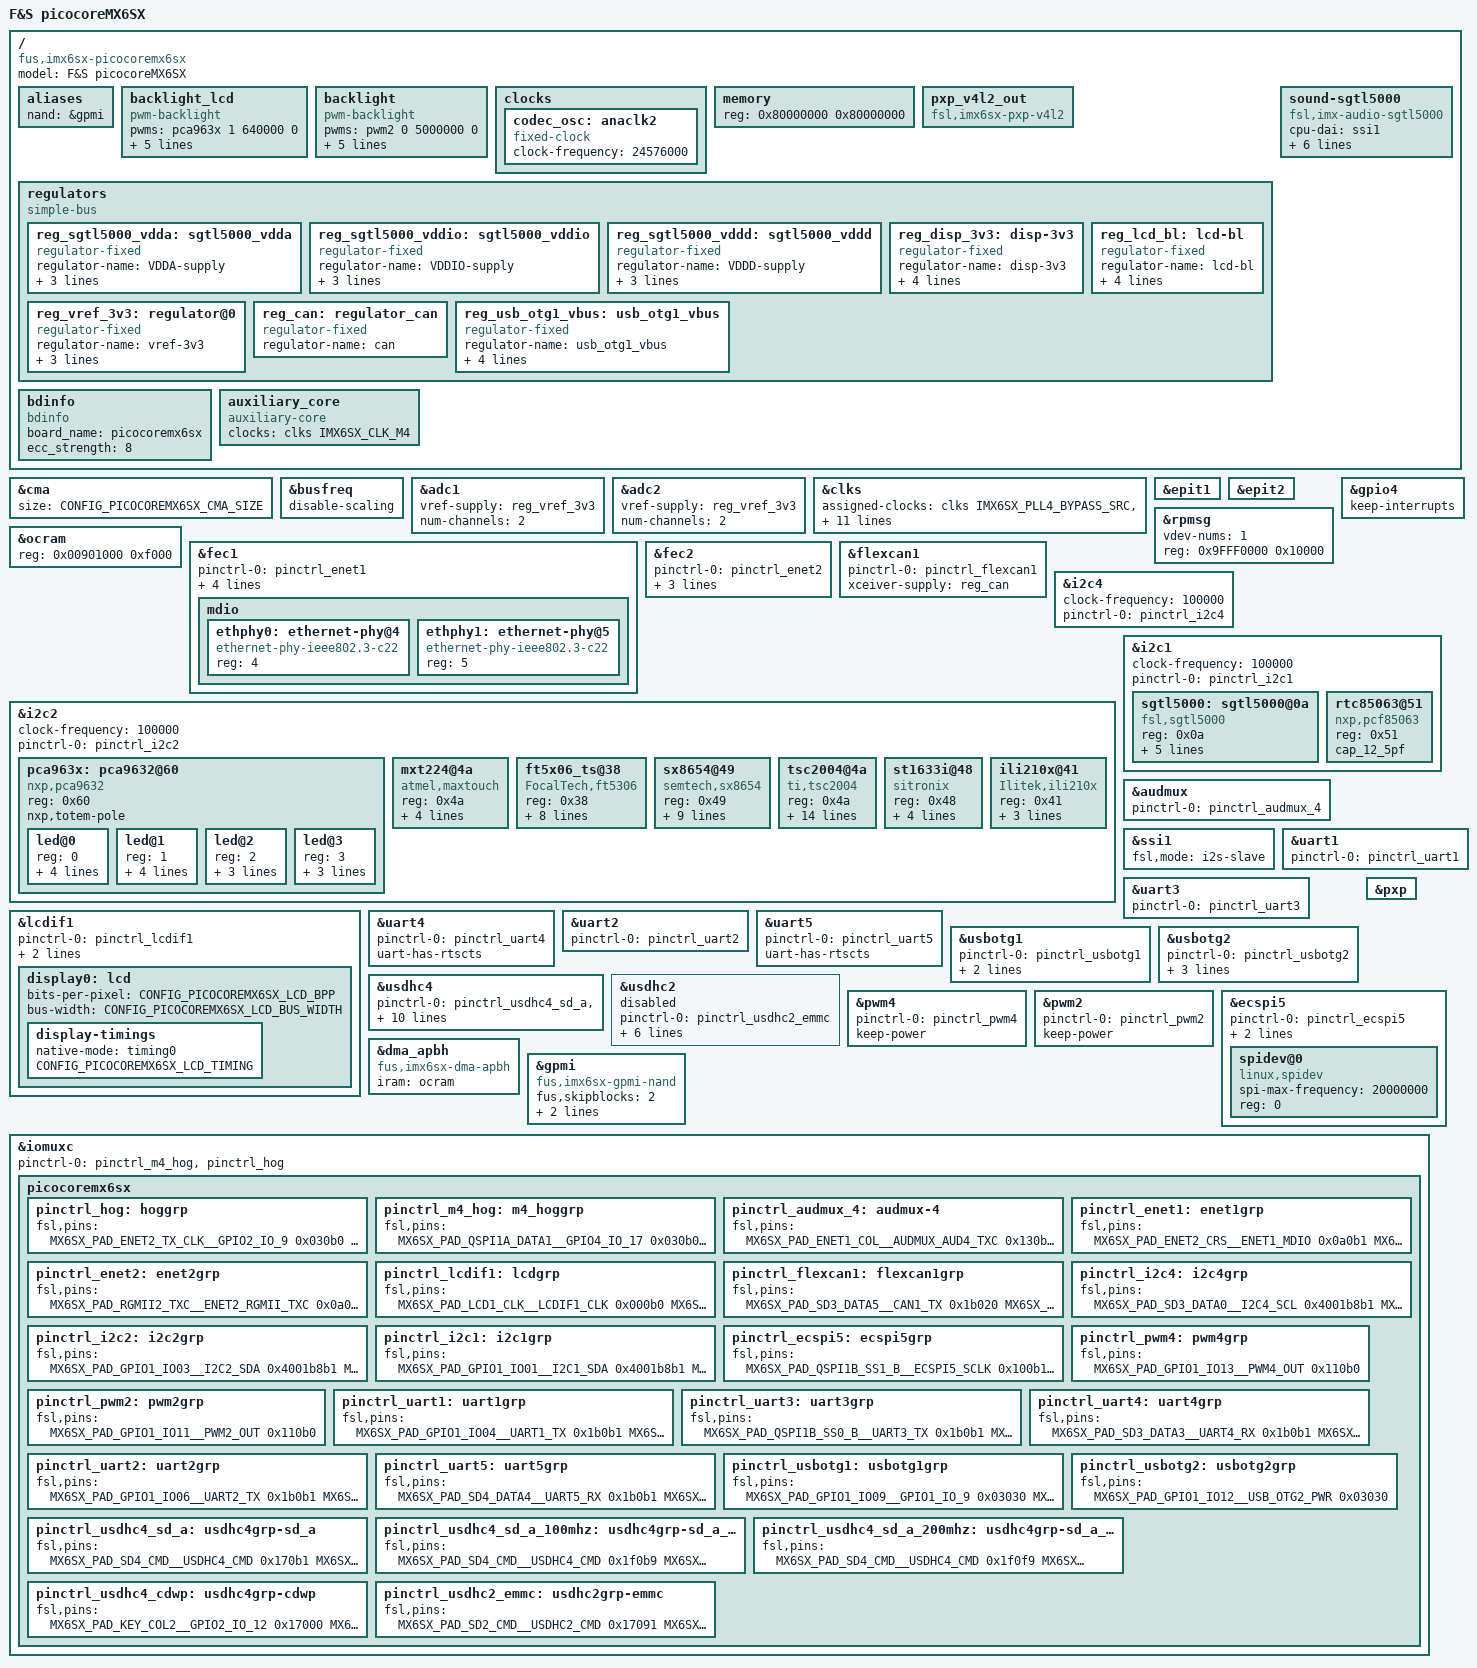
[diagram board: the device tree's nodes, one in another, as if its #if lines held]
/*
 * Copyright (C) 2016-2019 F&S Elektronik Systeme GmbH
 *
 * This program is free software; you can redistribute it and/or modify
 * it under the terms of the GNU General Public License version 2 as
 * published by the Free Software Foundation.
 */

/dts-v1/;

/* Set board revision as 3-digit number, e.g. 110 for board rev. 1.10 */
#define CONFIG_PICOCOREMX6SX_BOARD_REVISION	120

/* Activate this if you want to use the Cortex-M4 core */
// #define SUPPORT_M4

#define DISPLAY_NONE	0	/* No display on this port */
#define DISPLAY_LCD	1	/* LCD via RGB adapter */

/*
 * Set the display configuration:
 *
 * - If you have no display, set LCDIF0 to DISPLAY_NONE.
 * - If you have a display, set LCDIF0 to DISPLAY_LCD.
 */
#define CONFIG_PICOCOREMX6SX_LCDIF0		DISPLAY_LCD

/*
 * Configure LCD settings here (ignored if LCD is not used)
 */
#define CONFIG_PICOCOREMX6SX_LCD_BPP		32
#define CONFIG_PICOCOREMX6SX_LCD_BUS_WIDTH	24
#define CONFIG_PICOCOREMX6SX_LCD_TIMING \
lcd_wvga {				\
	clock-frequency = <33500000>;	\
	hactive = <800>;  		\
	vactive = <480>;		\
	hfront-porch = <40>;		\
	hback-porch = <88>;		\
	hsync-len = <128>;		\
	vback-porch = <33>;		\
	vfront-porch = <10>;		\
	vsync-len = <2>;		\
	hsync-active = <0>;		\
	vsync-active = <0>;		\
	de-active = <1>;		\
	pixelclk-active = <1>;		\
}

/* GPU is only available on CPU variants MCIMX6X3... and MCIMX6X4... */
#define CONFIG_PICOCOREMX6SX_GPU

/* Keep VLCD on when pca and touch are powered through VLCD */
//#define CONFIG_KEEP_VLCD_ON

/*
 * Configure touch screen:
 *
 * - 4-wire/5-wire analog resistive touch, touch controller on RGB LCD adapter
 * - PCAP touch based on Maxtouch controller (MXT224, etc.), on Touch Connector
 * - PCAP touch based on Focaltech controller (FT5x06), on Touch Connector
 * - PCAP touch based on Sitronix controller (ST1633i), on Touch Connector
 * - PCAP touch based on Ilitek controller (ILI12xx), on Touch Connector
 *
 * On picocore bb, all touches use the same interrupt line and I2C bus, so do not
 * select more than one entry! Select none if you do not need touch support.
 */
#define CONFIG_PICOCOREMX6SX_4WTOUCH_SX8655_RGBADAPTER
//#define CONFIG_PICOCOREMX6SX_4WTOUCH_TSC2004_RGBADAPTER
//#define CONFIG_PICOCOREMX6SX_CAPTOUCH_MXT224
//#define CONFIG_PICOCOREMX6SX_CAPTOUCH_FT5x06
//#define CONFIG_PICOCOREMX6SX_CAPTOUCH_SITRONIX
//#define CONFIG_PICOCOREMX6SX_CAPTOUCH_ILITEK

/* CMA: Set 320 MB for Continuous Memory Allocator */
#define CONFIG_PICOCOREMX6SX_CMA_SIZE 0x14000000

/* NAND */
/* eMMC */
/* Will be set by Uboot */


/* Network */
#define CONFIG_PICOCOREMX6SX_ETH0
#define CONFIG_PICOCOREMX6SX_ETH1

/* USB */
#define CONFIG_PICOCOREMX6SX_USB_OTG1
#define CONFIG_PICOCOREMX6SX_USB_HOST

/* CAN */
#define CONFIG_PICOCOREMX6SX_CAN_A

/* I2C */
#define CONFIG_PICOCOREMX6SX_I2C_A
#define CONFIG_PICOCOREMX6SX_I2C_B
#define CONFIG_PICOCOREMX6SX_I2C_C

/* ADC */
#define CONFIG_PICOCOREMX6SX_ADC_A
#define CONFIG_PICOCOREMX6SX_ADC_B

/* PWM and backlight brightness */
#define CONFIG_PICOCOREMX6SX_PWM_A
#define CONFIG_PICOCOREMX6SX_BL_CTRL

/* UART */
#define CONFIG_PICOCOREMX6SX_UART_A
#define CONFIG_PICOCOREMX6SX_UART_B
#define CONFIG_PICOCOREMX6SX_UART_C
#define CONFIG_PICOCOREMX6SX_UART_C_RTSCTS
#define CONFIG_PICOCOREMX6SX_UART_D
#define CONFIG_PICOCOREMX6SX_UART_E
#define CONFIG_PICOCOREMX6SX_UART_E_RTSCTS

/* SPI; SPI_B can only use CS2 if UART_C does not use RTS */
#define CONFIG_PICOCOREMX6SX_SPI_A

/* Audio */
#define CONFIG_PICOCOREMX6SX_AUDIO

/*
 * SD_A - External SD port with Card Detect (CD) and Write Protect (WP)
 * On PicoCore baseboard, this is the Micro-SD card slot with CD but without WP
 */
#define CONFIG_PICOCOREMX6SX_SD_A
#define CONFIG_PICOCOREMX6SX_SD_A_CD
//#define CONFIG_PICOCOREMX6SX_SD_A_WP

/* Check for invalid CONFIG combinations */

/*
 * Exclude devices from Linux that are used by the Cortex-M4 FreeRTOS examples
 *
 * - UART_B: used for debug output/UART examples
 * - SPI_B:  MISO/MOSI/CLK/CS1 used in SPI examples
 * - PWM_A:  used as LED output
 *
 * In addition the following pins are already predefined in FreeRTOS to be used
 * as arbitrary GPIOs. Please remove the comment of the appropriate line of
 * each device from which you use any signal in your own application.
 *
 * - SPI_A:  MISO/MOSI/CLK/CS1/CS2
 * - CAN_A:  TX/RX
 * - I2C_A:  SCL/SDA
 * - BL_CTL: (PWM)
 */
#ifdef SUPPORT_M4
#undef CONFIG_PICOCOREMX6SX_UART_B
#undef CONFIG_PICOCOREMX6SX_SPI_A
#undef CONFIG_PICOCOREMX6SX_CAN_A
#undef CONFIG_PICOCOREMX6SX_I2C_A
#undef CONFIG_PICOCOREMX6SX_BL_CTRL
#endif

/* If UART_C is not used, also RTS/CTS may not be used */
#ifndef CONFIG_PICOCOREMX6SX_UART_C
#undef CONFIG_PICOCOREMX6SX_UART_C_RTSCTS
#endif

#include "imx6sx.dtsi"
#include <dt-bindings/pwm/pwm.h>

/ {
	model = "F&S picocoreMX6SX";
	compatible = "fus,imx6sx-picocoremx6sx", "fsl,imx6sx";

	aliases {
		nand=&gpmi;
	};

#if defined(CONFIG_PICOCOREMX6SX_I2C_B) && (CONFIG_PICOCOREMX6SX_LCDIF0 == DISPLAY_LCD)
	backlight_lcd {
		compatible = "pwm-backlight";
		pwms = <&pca963x 1 640000 0>;
		power-supply = <&reg_lcd_bl>;
		brightness-levels = <0 1 5 10 18 28 41 56
				     73 92 113 137 163 192 222 255>;
		default-brightness-level = <14>;
		fb-names = "mxs-lcdif0";
	};
#endif

#if defined(CONFIG_PICOCOREMX6SX_BL_CTRL) && (CONFIG_PICOCOREMX6SX_LCDIF0 == DISPLAY_LCD)
	backlight {
		compatible = "pwm-backlight";
		pwms = <&pwm2 0 5000000 0>;
		power-supply = <&reg_lcd_bl>;
		brightness-levels = <0 1 5 10 18 28 41 56
				     73 92 113 137 163 192 222 255>;
		default-brightness-level = <14>;
		fb-names = "mxs-lcdif0";
	};
#endif

	clocks {
		codec_osc: anaclk2 {
			#clock-cells = <0>;
			compatible = "fixed-clock";
			clock-frequency = <24576000>;
		};
	};

	memory {
		reg = <0x80000000 0x80000000>;
	};

	pxp_v4l2_out {
		compatible = "fsl,imx6sx-pxp-v4l2", "fsl,imx6sl-pxp-v4l2";
		status = "okay";
	};

	regulators {
		compatible = "simple-bus";
		#address-cells = <1>;
		#size-cells = <0>;

#ifdef CONFIG_PICOCOREMX6SX_AUDIO
		/* SGTL5000 analog voltage */
		reg_sgtl5000_vdda: sgtl5000_vdda {
			compatible = "regulator-fixed";
			regulator-name = "VDDA-supply";
			regulator-min-microvolt = <3000000>;
			regulator-max-microvolt = <3000000>;
			regulator-always-on;
		};

		/* SGTL5000 I/O voltage */
		reg_sgtl5000_vddio: sgtl5000_vddio {
			compatible = "regulator-fixed";
			regulator-name = "VDDIO-supply";
			regulator-min-microvolt = <3300000>;
			regulator-max-microvolt = <3300000>;
			regulator-always-on;
		};

		/* SGTL5000 internal digital voltage */
		reg_sgtl5000_vddd: sgtl5000_vddd {
			compatible = "regulator-fixed";
			regulator-name = "VDDD-supply";
			regulator-min-microvolt = <1500000>;
			regulator-max-microvolt = <1500000>;
			regulator-always-on;
		};
#endif

#if (CONFIG_PICOCOREMX6SX_LCDIF0 == DISPLAY_LCD)
#ifndef CONFIG_KEEP_VLCD_ON
		reg_disp_3v3: disp-3v3 {
			compatible = "regulator-fixed";
			regulator-name = "disp-3v3";
			gpio = <&gpio3 27 0>;
			regulator-min-microvolt = <3300000>;
			regulator-max-microvolt = <3300000>;
			enable-active-high;
		};
#endif
#endif

#if defined(CONFIG_PICOCOREMX6SX_I2C_B) && (CONFIG_PICOCOREMX6SX_LCDIF0 == DISPLAY_LCD)
		reg_lcd_bl: lcd-bl {
			compatible = "regulator-fixed";
			regulator-name = "lcd-bl";
			gpio = <&pca963x 0 0>;
			regulator-min-microvolt = <3300000>;
			regulator-max-microvolt = <3300000>;
			enable-active-high;
		};
#endif

#if 0
		reg_atmel_mxt_vdd: atmel_mxt_vdd {
			compatible = "regulator-fixed";
			regulator-name = "mxt-3v3";
			status = "enabled";
		};

		reg_atmel_mxt_avdd: atmel_mxt_avdd {
			compatible = "regulator-fixed";
			regulator-name = "mxt-3v3";
			status = "enabled";
		};
#endif

		reg_vref_3v3: regulator@0 {
			compatible = "regulator-fixed";
			regulator-name = "vref-3v3";
			regulator-min-microvolt = <3300000>;
			regulator-max-microvolt = <3300000>;
			regulator-always-on;
		};

#ifdef CONFIG_PICOCOREMX6SX_CAN_A
		reg_can: regulator_can {
			compatible = "regulator-fixed";
			regulator-name = "can";
		};
#endif /* CONFIG_PICOCOREMX6SX_CAN_A */

#ifdef CONFIG_PICOCOREMX6SX_USB_OTG1
		/* USB_OTG1_PWR done by USB controller, no regulator needed */
		reg_usb_otg1_vbus: usb_otg1_vbus {
			compatible = "regulator-fixed";
			regulator-name = "usb_otg1_vbus";
			regulator-min-microvolt = <5000000>;
			regulator-max-microvolt = <5000000>;
			gpio = <&gpio1 9 0>;
			enable-active-high;
		};
#endif /* CONFIG_PICOCOREMX6SX_USB_OTG1 */

#if 0
		/* USB_OTG2_PWR done by USB controller, no regulator needed */
		reg_usb_otg2_vbus: usb_otg2_vbus {
			compatible = "regulator-fixed";
			regulator-name = "usb_otg2_vbus";
			regulator-min-microvolt = <5000000>;
			regulator-max-microvolt = <5000000>;
			gpio = <&gpio1 12 0>;
			enable-active-high;
		};
#endif
	};


#ifdef CONFIG_PICOCOREMX6SX_AUDIO
	sound-sgtl5000 {
		compatible = "fsl,imx-audio-sgtl5000";
		cpu-dai = <&ssi1>;
		audio-codec = <&sgtl5000>;
		model = "imx-sgtl5000";
		mux-int-port = <1>;  /* SSI1=1, SSI2=2, SSI3=7 */
		mux-ext-port = <4>;
		audio-routing =
			"LINE_IN", "Line In Jack",
//###			"MIC_IN", "Mic Jack",
//###			"Line Out Jack", "LINE_OUT",
			"Headphone Jack", "HP_OUT";
	};
#endif

	/* F&S board information */
	bdinfo {
		compatible = "bdinfo";
		board_name = "picocoremx6sx";
		ecc_strength = "8";
	};

#ifdef SUPPORT_M4
	/* F&S auxiliary core driver */
	auxiliary_core {
		compatible = "auxiliary-core";
		clocks = <&clks IMX6SX_CLK_M4>;
	};
#endif
};

/* RAM size for Continues Memory Allocator */
&cma {
	size = <CONFIG_PICOCOREMX6SX_CMA_SIZE>;
};

&busfreq {
	/* Disable bus frequency scaling, because reducing bus frequency to
	   24 MHz does not work with all types of DDR3 RAM */
	disable-scaling;
};

&adc1 {
	vref-supply = <&reg_vref_3v3>;
	num-channels = <2>;
	status = "okay";
};

&adc2 {
	vref-supply = <&reg_vref_3v3>;
	num-channels = <2>;
	status = "okay";
};

&clks {
	assigned-clocks = <&clks IMX6SX_PLL4_BYPASS_SRC>,
			  <&clks IMX6SX_PLL4_BYPASS>,
			  <&clks IMX6SX_CLK_PLL4_POST_DIV>;
	assigned-clock-parents = <&clks IMX6SX_CLK_LVDS2_IN>,
				 <&clks IMX6SX_PLL4_BYPASS_SRC>;
	assigned-clock-rates = <0>, <0>, <24576000>;
/* Needed for low power mode to tell A9 which clocks might be shared with M4 */
#ifdef SUPPORT_M4
	/* Shared memory in OCRAM, keep clear from Linux */
	fsl,shared-mem-addr = <0x91F000>;
	fsl,shared-mem-size = <0x1000>;
	fsl,shared-clks-number = <0x23>;
	fsl,shared-clks-index = <IMX6SX_CLK_PLL2_BUS
				 IMX6SX_CLK_PLL2_PFD0
				 IMX6SX_CLK_PLL2_PFD2
				 IMX6SX_CLK_PLL3_USB_OTG
				 IMX6SX_CLK_PLL3_PFD1
				 IMX6SX_CLK_PLL3_PFD2
				 IMX6SX_CLK_PLL3_PFD3
				 IMX6SX_CLK_PLL4_AUDIO
				 IMX6SX_CLK_PLL5_VIDEO
				 IMX6SX_CLK_OCRAM
				 IMX6SX_CLK_CAN1_SERIAL
				 IMX6SX_CLK_CAN1_IPG
				 IMX6SX_CLK_CAN2_SERIAL
				 IMX6SX_CLK_CAN2_IPG
				 IMX6SX_CLK_CANFD
				 IMX6SX_CLK_ECSPI1
				 IMX6SX_CLK_ECSPI2
				 IMX6SX_CLK_ECSPI3
				 IMX6SX_CLK_ECSPI4
				 IMX6SX_CLK_ECSPI5
				 IMX6SX_CLK_QSPI1
				 IMX6SX_CLK_QSPI2
				 IMX6SX_CLK_SSI1
				 IMX6SX_CLK_SSI2
				 IMX6SX_CLK_SSI3
				 IMX6SX_CLK_UART_SERIAL
				 IMX6SX_CLK_UART_IPG
				 IMX6SX_CLK_PERIPH_CLK2_SEL
				 IMX6SX_CLK_DUMMY
				 IMX6SX_CLK_I2C1
				 IMX6SX_CLK_I2C2
				 IMX6SX_CLK_I2C3
				 IMX6SX_CLK_I2C4
				 IMX6SX_CLK_EPIT1
				 IMX6SX_CLK_EPIT2>;
#endif
};

#ifdef SUPPORT_M4
/* epit1 and epit2 are used by Cortex-M4 examples for timing purposes */
&epit1{
	status = "okay";
};


&epit2{
	status = "okay";
};

/* rpmsg is used for communication between Cortex-A9 and Cortex-M4 cores */

&rpmsg{
	/*
	 * 64K for one rpmsg instance, default using 2 rpmsg instances:
	 * --0x9FF00000~0x9FF0FFFF: pmic,pm,audio,keys,gpio,sensor
	 * --0x9FF10000~0x9FF1FFFF: pingpong,virtual tty
	 */
	vdev-nums = <1>;
	reg = <0x9FFF0000 0x10000>;
	status = "okay";
};

/* Keep interrupts on GPIO4 if M4 already owns it */
&gpio4 {
	keep-interrupts;
};

/*
 * OCRAM usage (128KB):
 *   0x00900000 - 0x00900FFF: Cortex-A9/Linux: CPU idle + bus frequency code
 *   0x00901000 - 0x0090FFFF: Cortex-A9/Linux: DMA descriptors, GPU
 *   0x00910000 - 0x0091EFFF: Cortex-M4/FreeRTOS: Code/Data
 *   0x0091F000 - 0x0091FFFF: Cortex-A9+M4: Shared memory for shared clocks
 */
&ocram {
	reg = <0x00901000 0xf000>;
};
#endif

#ifdef CONFIG_PICOCOREMX6SX_ETH0
&fec1 {
	pinctrl-names = "default";
	pinctrl-0 = <&pinctrl_enet1>;
	phy-mode = "rgmii-id";
	phy-handle = <&ethphy0>;
	phy-supply = <&reg_vref_3v3>;
	fsl,magic-packet;
	status = "okay";

	/* The MDIO bus on FEC1 holds both PHYs */
	mdio {
		#address-cells = <1>;
		#size-cells = <0>;

		ethphy0: ethernet-phy@4 {
			compatible = "ethernet-phy-ieee802.3-c22";
			reg = <4>;
		};

#ifdef CONFIG_PICOCOREMX6SX_ETH1
		ethphy1: ethernet-phy@5 {
			compatible = "ethernet-phy-ieee802.3-c22";
			reg = <5>;
		};
#endif
	};
};
#endif /* CONFIG_PICOCOREMX6SX_ETH0 */

#ifdef CONFIG_PICOCOREMX6SX_ETH1
&fec2 {
	pinctrl-names = "default";
	pinctrl-0 = <&pinctrl_enet2>;
	phy-mode = "rgmii-id";
	phy-handle = <&ethphy1>;
	fsl,magic-packet;
	status = "okay";
};
#endif /* CONFIG_PICOCOREMX6SX_ETH1 */

#ifdef CONFIG_PICOCOREMX6SX_CAN_A
&flexcan1 {
	pinctrl-names = "default";
	pinctrl-0 = <&pinctrl_flexcan1>;
	xceiver-supply = <&reg_can>;
	status = "okay";
};
#endif

#ifdef CONFIG_PICOCOREMX6SX_I2C_A
&i2c4 {
	clock-frequency = <100000>;
	pinctrl-names = "default";
	pinctrl-0 = <&pinctrl_i2c4>;
	status = "okay";
};

#endif /* CONFIG_PICOCOREMX6SX_I2C_A */

#ifdef CONFIG_PICOCOREMX6SX_I2C_B
/*
 * I2C_A implemented via I2C2
 * On picocore bb: RGB adapter, SX8655, touch connnector, feature connector
 */
&i2c2 {
	clock-frequency = <100000>;
	pinctrl-names = "default";
	pinctrl-0 = <&pinctrl_i2c2>;
	status = "okay";

	pca963x: pca9632@60 {
		compatible = "nxp,pca9632";
		reg = <0x60>;
		nxp,totem-pole;
		#address-cells = <1>;
		#size-cells = <0>;
		#pwm-cells = <3>;
		#gpio-cells = <2>;
		led@0 {
			reg = <0>;
			label = "0-PWRCTL";
			type = "GPIO";
			default-on;		/* or: keep-value */
			active-high;
		};
		led@1 {
			reg = <1>;
			label = "1-LEDCTRL";
			type = "PWM";
			default-on;		/* or: keep-value */
			active-low;
		};
		led@2 {
			reg = <2>;
			label = "2-ROTATE";
			type = "GPIO";
			active-high;		/* optionally: keep value */
		};
		led@3 {
			reg = <3>;
			label = "3-unused";
			type = "LED";
			active-low;
		};
	};

#ifdef CONFIG_PICOCOREMX6SX_CAPTOUCH_MXT224
	mxt224@4a {
		compatible = "atmel,maxtouch";
		reg = <0x4a>;
		interrupt-parent = <&gpio7>;
		interrupts = <0 2>;
		atmel,cfg_name = "atmel/mxt224.cfg";
		atmel,reset-gpio = <&gpio3 21 GPIO_ACTIVE_LOW>;
#if 0
		atmel,suspend-mode = <2>;
		vdd = <&reg_atmel_mxt_vdd>;
		avdd = <&reg_atmel_mxt_avdd>;
#endif
	};
#endif

        /* Touch driver Focaltech  */
#if 0
	/* Mainline driver, may only work on EDT displays */
	edt-ft5x06@38 {
		compatible = "edt,edt-ft5306";
		reg = <0x38>;
		threshold = <25>;
		gain = <8>;
		offset = <0>;
		interrupt-parent = <&gpio7>;
		interrupts = <0 IRQ_TYPE_EDGE_FALLING>;
		reset-gpios = <&gpio3 21 GPIO_ACTIVE_LOW>;
	};
#else

#ifdef CONFIG_PICOCOREMX6SX_CAPTOUCH_FT5x06
	/* F&S driver V3.0 */
	ft5x06_ts@38 {
		compatible = "FocalTech,ft5306";
		reg = <0x38>;
		fingers = <2>;
		touchscreen-size-x = <800>;
		touchscreen-size-y = <480>;
		threshold = <25>;
		interrupt-parent = <&gpio7>;
		interrupts = <0 IRQ_TYPE_EDGE_FALLING>;
		reset-gpios = <&gpio3 21 GPIO_ACTIVE_LOW>;
		linux,wakeup;
	};
#endif

#endif

	/* Touch driver SX8654 */
#ifdef CONFIG_PICOCOREMX6SX_4WTOUCH_SX8655_RGBADAPTER
	sx8654@49 {
		compatible = "semtech,sx8654";
		reg = <0x49>;
		touchrate = <0x30>;
		powdly = <0x06>;
		filt = <0x02>;
		setdly = <0x08>;
		pinctrl-names = "default";
		/*pinctrl-0 = <&pinctrl_touchscreen>;*/
		interrupt-parent = <&gpio1>;
		interrupts = <8 IRQ_TYPE_EDGE_FALLING>;
		reset-gpio = <&gpio3 21 GPIO_ACTIVE_LOW>;
		x-rev;
		y-rev;
	};
#endif

#ifdef CONFIG_PICOCOREMX6SX_4WTOUCH_TSC2004_RGBADAPTER
	/* 4/5 wire analog resistive touch on RGB-Adapter */
	tsc2004@4a {
		compatible = "ti,tsc2004";
		reg = <0x4a>;
		vio-supply = <&reg_vref_3v3>;
		interrupts-extended = <&gpio1 8 IRQ_TYPE_EDGE_FALLING>;
		reset-gpio = <&gpio3 21 GPIO_ACTIVE_LOW>;
		touchscreen-fuzz-x = <4>;
		touchscreen-fuzz-y = <7>;
		touchscreen-fuzz-pressure = <20>;
		touchscreen-size-x = <4096>;
		touchscreen-size-y = <4096>;
		touchscreen-max-pressure = <2048>;
		touchscreen-inverted-y;
		ti,x-plate-ohms = <280>;
		ti,pre-charge-time = <4>;
		ti,sense-time-sel = <3>;
	};
#endif

#ifdef CONFIG_PICOCOREMX6SX_CAPTOUCH_SITRONIX
	/* Sitronix PCAP touch on Touch-Connector (I2C) */
	st1633i@48 {
		compatible = "sitronix";
		reg = <0x48>;
		swap-xy;
		interrupt-parent = <&gpio7>;
		interrupts = <0 IRQ_TYPE_EDGE_FALLING>;
		reset-gpio = <&gpio3 21 GPIO_ACTIVE_LOW>;
	};
#endif

#ifdef CONFIG_PICOCOREMX6SX_CAPTOUCH_ILITEK
	/* Ilitek PCAP touch on Touch-Connector (I2C) */
	ili210x@41 {
		compatible = "Ilitek,ili210x";
		reg = <0x41>;
		interrupt-parent = <&gpio7>;
		interrupts = <0 IRQ_TYPE_EDGE_FALLING>;
		reset-gpio = <&gpio3 21 GPIO_ACTIVE_LOW>;
	};
#endif

#if 0
	egalax_ts@04 {
		compatible = "eeti,egalax_ts";
		reg = <0x04>;
		interrupt-parent = <&gpio6>;
		interrupts = <22 2>;
		wakeup-gpios = <&gpio6 22 0>;
	};
#endif
};
#endif /* CONFIG_PICOCOREMX6SX_I2C_B */


#ifdef CONFIG_PICOCOREMX6SX_I2C_C
/*
 * I2C_C implemented via I2C1; used for on-board RTC, on-board LVDS connector;
 * On picocore bb: Audio Codec (SGTL5000), HDMI
 */
&i2c1 {
	clock-frequency = <100000>;
	pinctrl-names = "default";
	pinctrl-0 = <&pinctrl_i2c1>;
	status = "okay";

#ifdef CONFIG_PICOCOREMX6SX_AUDIO
	sgtl5000: sgtl5000@0a {
		compatible = "fsl,sgtl5000";
		reg = <0x0a>;
		mono2both;
		clocks = <&clks IMX6SX_CLK_AUDIO>;
		VDDA-supply = <&reg_sgtl5000_vdda>;
		VDDIO-supply = <&reg_sgtl5000_vddio>;
		VDDD-supply = <&reg_sgtl5000_vddd>;
	};
#endif

	rtc85063@51 {
		compatible = "nxp,pcf85063";
		reg = <0x51>;
		cap_12_5pf;
	};
};
#endif /* CONFIG_PICOCOREMX6SX_I2C_C */

#ifdef CONFIG_PICOCOREMX6SX_AUDIO
&audmux {
	pinctrl-names = "default";
	pinctrl-0 = <&pinctrl_audmux_4>;
	status = "okay";
};

&ssi1 {
//###	fsl,mode = "i2s-master";
	fsl,mode = "i2s-slave";
	status = "okay";
};
#endif /* CONFIG_PICOCOREMX6SX_AUDIO */

#if (CONFIG_PICOCOREMX6SX_LCDIF0 == DISPLAY_LCD)
&lcdif1 {
	pinctrl-names = "default";
	pinctrl-0 = <&pinctrl_lcdif1>;		/* Remove when already active */
	display = <&display0>;			/* Remove when already active */
#ifndef CONFIG_KEEP_VLCD_ON
	lcd-supply = <&reg_disp_3v3>;
#endif
	// pattern = <5>;
	status = "okay";

	display0: lcd {
		bits-per-pixel = <CONFIG_PICOCOREMX6SX_LCD_BPP>;
		bus-width = <CONFIG_PICOCOREMX6SX_LCD_BUS_WIDTH>;

		display-timings {
			native-mode = <&timing0>;
			timing0: CONFIG_PICOCOREMX6SX_LCD_TIMING;
		};
	};
};
#endif /* CONFIG_PICOCOREMX6SX_LCDIF0 */

#ifndef CONFIG_PICOCOREMX6SX_GPU
&gpu {
	status = "disabled";
};
#endif


#ifdef CONFIG_PICOCOREMX6SX_UART_A
/* UART_A implemented by UART1: TXD, RXD only */
&uart1 {
	pinctrl-names = "default";
	pinctrl-0 = <&pinctrl_uart1>;
	status = "okay";
};
#endif /* CONFIG_PICOCOREMX6SX_UART_A */

#ifdef CONFIG_PICOCOREMX6SX_UART_B
/* UART_B implemented by UART3: TXD, RXD only */
&uart3 {
	pinctrl-names = "default";
	pinctrl-0 = <&pinctrl_uart3>;
	status = "okay";
};
#endif /* CONFIG_PICOCOREMX6SX_UART_B */

#ifdef CONFIG_PICOCOREMX6SX_UART_C
/* UART_C implemented by UART4: TXD, RXD,  RTS, CTS */
&uart4 {
	pinctrl-names = "default";
	pinctrl-0 = <&pinctrl_uart4>;
#ifdef CONFIG_PICOCOREMX6SX_UART_C_RTSCTS
	uart-has-rtscts;
#endif
	status = "okay";
};
#endif /* CONFIG_PICOCOREMX6SX_UART_C */

#ifdef CONFIG_PICOCOREMX6SX_UART_D
/* UART_D implemented by UART2: TXD, RXD only */
&uart2 {
	pinctrl-names = "default";
	pinctrl-0 = <&pinctrl_uart2>;
	status = "okay";
};
#endif /* CONFIG_PICOCOREMX6SX_UART_D */

#ifdef CONFIG_PICOCOREMX6SX_UART_E
/*  UART_E implemented by UART5: TXD, RXD, RTS, CTS */
&uart5 {
	pinctrl-names = "default";
	pinctrl-0 = <&pinctrl_uart5>;
#ifdef CONFIG_PICOCOREMX6SX_UART_E_RTSCTS
	uart-has-rtscts;
#endif
	status = "okay";
};
#endif /* CONFIG_PICOCOREMX6SX_UART_E */

#ifdef CONFIG_PICOCOREMX6SX_USB_OTG1
&usbotg1 {
	pinctrl-names = "default";
	pinctrl-0 = <&pinctrl_usbotg1>;
	vbus-supply = <&reg_usb_otg1_vbus>;
	disable-over-current;
	status = "okay";
};
#endif

#ifdef CONFIG_PICOCOREMX6SX_USB_HOST
&usbotg2 {
	pinctrl-names = "default";
	pinctrl-0 = <&pinctrl_usbotg2>;
//	vbus-supply = <&reg_usb_otg2_vbus>;
	dr_mode = "host";
	pwr-active-high;
	disable-over-current;
	status = "okay";
};
#endif

#ifdef CONFIG_PICOCOREMX6SX_SD_A
/* SD_A implemented via USDHC4 on board revisions since 1.20 */
&usdhc4 {
	pinctrl-names = "default", "state_100mhz", "state_200mhz";
	pinctrl-0 = <&pinctrl_usdhc4_sd_a &pinctrl_usdhc4_cdwp>;
	pinctrl-1 = <&pinctrl_usdhc4_sd_a_100mhz &pinctrl_usdhc4_cdwp>;
	pinctrl-2 = <&pinctrl_usdhc4_sd_a_200mhz &pinctrl_usdhc4_cdwp>;
#ifdef CONFIG_PICOCOREMX6SX_SD_A_CD
	cd-gpios = <&gpio2 12 GPIO_ACTIVE_LOW>;
#else
	non-removable;
#endif
#ifdef CONFIG_PICOCOREMX6SX_SD_A_WP
	wp-gpios = <&gpio2 17 GPIO_ACTIVE_HIGH>;
#endif
	bus-width = <4>;
	vmmc-supply = <&reg_vref_3v3>;	/* VDD */
	keep-power-in-suspend;
	status = "okay";
};
#endif /* CONFIG_PICOCOREMX6SX_SD_A */

/* Keep disabled. Will be activated by Uboot
 * if eMMC is used as boot device.
 */
&usdhc2 {
	pinctrl-names = "default";
	pinctrl-0 = <&pinctrl_usdhc2_emmc>;
	bus-width = <8>;
	vmmc-supply = <&reg_vref_3v3>;
	vqmmc-supply = <&reg_vref_3v3>;
	voltage-ranges = <3300 3300>;
	no-1-8-v;
	keep-power-in-suspend;
	status = "disabled";
};

#ifdef CONFIG_PICOCOREMX6SX_PWM_A
/* PWM_A implemented by PWM4 */
&pwm4 {
	pinctrl-names = "default";
	pinctrl-0 = <&pinctrl_pwm4>;
	keep-power;		/* Necessary if PWM is inverted */
	status = "okay";
};
#endif /* CONFIG_PICOCOREMX6SX_PWM_A */

#ifdef CONFIG_PICOCOREMX6SX_BL_CTRL
/* Backlight PWM implemented by PWM2 */
&pwm2 {
	pinctrl-names = "default";
	pinctrl-0 = <&pinctrl_pwm2>;
	keep-power;		/* Necessary if PWM is inverted */
	status = "okay";
};
#endif /* CONFIG_PICOCOREMX6SX_BL_CTRL */

#ifdef CONFIG_PICOCOREMX6SX_ADC_A
&adc1 {
	vref-supply = <&reg_vref_3v3>;
	status = "okay";
};
#endif

#ifdef CONFIG_PICOCOREMX6SX_ADC_B
&adc2 {
	vref-supply = <&reg_vref_3v3>;
	status = "okay";
};
#endif

&pxp {
	status = "okay";
};

#ifdef CONFIG_PICOCOREMX6SX_SPI_A
/* SPI_A implemented via ECSPI5, 1x CS */
&ecspi5 {
	pinctrl-names = "default";
	pinctrl-0 = <&pinctrl_ecspi5>;
	fsl,spi-num-chipselects = <1>;
	cs-gpios = <&gpio4 28 0>;
	status = "okay";

	spidev@0 {
		#address-cells = <1>;
		#size-cells = <1>;
		compatible = "linux,spidev";
		spi-max-frequency = <20000000>;
		reg = <0>;
	};
};
#endif /* CONFIG_PICOCOREMX6SX_SPI_A */

&dma_apbh {
	/* Switch to F&S implementation of APBH DMA driver for GPMI (NAND) */
	compatible = "fus,imx6sx-dma-apbh", "fus,imx28-dma-apbh";
	iram = <&ocram>;
};

&gpmi {
	/* Switch to F&S implementation of GPMI NAND driver */
	compatible = "fus,imx6sx-gpmi-nand";
	pinctrl-names = "default";
//###	pinctrl-0 = <&pinctrl_gpmi_nand>;
	fus,skipblocks = <2>;
	fus,chunk1k;
	fus,ecc_strength = <8>;		/* Spare area 64 bytes */
//###	fus,ecc_strength = <52>;	/* Spare area 224 bytes */
	status = "okay";
};

&iomuxc {
	pinctrl-names = "default";
	pinctrl-0 =
#ifndef SUPPORT_M4
					<&pinctrl_m4_hog>,
#endif
					<&pinctrl_hog>;

	picocoremx6sx {
		pinctrl_hog: hoggrp {
			fsl,pins = <
				/* GPIO */
				MX6SX_PAD_ENET2_TX_CLK__GPIO2_IO_9	0x030b0
				MX6SX_PAD_KEY_COL0__GPIO2_IO_10		0x030b0
				MX6SX_PAD_KEY_COL1__GPIO2_IO_11		0x030b0
				MX6SX_PAD_KEY_COL3__GPIO2_IO_13		0x030b0
				MX6SX_PAD_KEY_COL4__GPIO2_IO_14		0x030b0
				MX6SX_PAD_KEY_ROW0__GPIO2_IO_15		0x030b0
				MX6SX_PAD_KEY_ROW3__GPIO2_IO_18		0x030b0
				MX6SX_PAD_KEY_ROW4__GPIO2_IO_19		0x030b0
				MX6SX_PAD_QSPI1A_DATA0__GPIO4_IO_16	0x030b0
				MX6SX_PAD_QSPI1B_DATA0__GPIO4_IO_24	0x030b0
				MX6SX_PAD_SD3_DATA4__GPIO7_IO_6		0x030b0
				MX6SX_PAD_SD3_DATA6__GPIO7_IO_8		0x030b0

				/* I2C2 IRQn */
				MX6SX_PAD_GPIO1_IO08__GPIO1_IO_8	0x0b0b0

				/* VLCD_ON - active high */
#ifndef CONFIG_KEEP_VLCD_ON
				MX6SX_PAD_LCD1_RESET__GPIO3_IO_27	0x130b0
#else
				/* ### HW-Bug:
				 * There is a hardware bug on the Starterkit
				 * baseboard PicoCoreBBRGB Rev 1.20. Instead of
				 * constantly being powered, the PCA9632 chip on
				 * the RGB display adapter, responsible for LCD
				 * logic power and backlight brightness, depends
				 * on VLCD_ON itself. Because VLCD_ON is low on
				 * startup, the PCA9632 chip is not powered and
				 * can not be initialized, causing the display
				 * to fail. The same happens for the touch
				 * controller at startup of Yocto, because the
				 * LCD is powered down during changes in buffer.
				 * By defining CONFIG_KEEP_VLCD_ON, you can use
				 * a workaround that keeps VLCD_ON high all the
				 * time. Then the display will work (with some
				 * restrictions).
				 * Please note that this is not a bug on the
				 * PicoCoreMX6SX module itself, only on the
				 * Starterkit baseboard.
				 */
				MX6SX_PAD_LCD1_RESET__GPIO3_IO_27	0x1b0b0
#endif

				/* PHY_RST */
				MX6SX_PAD_ENET1_MDC__GPIO2_IO_2		0x0b0b0

				/* DVS */
				MX6SX_PAD_USB_H_STROBE__GPIO7_IO_11	0x130b0
			>;
		};

		pinctrl_m4_hog: m4_hoggrp {
			fsl,pins = <
				MX6SX_PAD_QSPI1A_DATA1__GPIO4_IO_17	0x030b0
				MX6SX_PAD_QSPI1A_DATA2__GPIO4_IO_18	0x030b0
				MX6SX_PAD_QSPI1A_DATA3__GPIO4_IO_19	0x030b0
				MX6SX_PAD_QSPI1A_SCLK__GPIO4_IO_21	0x030b0
				MX6SX_PAD_QSPI1A_SS0_B__GPIO4_IO_22	0x030b0
				MX6SX_PAD_QSPI1B_DATA1__GPIO4_IO_25	0x030b0
				MX6SX_PAD_QSPI1B_DATA2__GPIO4_IO_26	0x030b0
				MX6SX_PAD_QSPI1B_DATA3__GPIO4_IO_27	0x030b0

			>;
		};

#ifdef CONFIG_PICOCOREMX6SX_AUDIO
		pinctrl_audmux_4: audmux-4 {
			fsl,pins = <
				MX6SX_PAD_ENET1_COL__AUDMUX_AUD4_TXC	0x130b0
				MX6SX_PAD_ENET1_CRS__AUDMUX_AUD4_TXD	0x130b0
				MX6SX_PAD_ENET1_TX_CLK__AUDMUX_AUD4_RXD 0x130b0
				MX6SX_PAD_ENET1_RX_CLK__AUDMUX_AUD4_TXFS 0x130b0
				MX6SX_PAD_ENET1_MDIO__AUDMUX_MCLK	0x130b0
			>;
		};
#endif

#ifdef CONFIG_PICOCOREMX6SX_ETH0
		pinctrl_enet1: enet1grp {
			fsl,pins = <
				/* MDIO */
				MX6SX_PAD_ENET2_CRS__ENET1_MDIO		0x0a0b1
				MX6SX_PAD_ENET2_COL__ENET1_MDC		0x0a0b1

				/* FEC1 */
				MX6SX_PAD_ENET2_RX_CLK__ENET2_REF_CLK_25M 0x0a0b9
//				MX6SX_PAD_ENET1_TX_CLK__ENET1_REF_CLK1	0x0a0b1
				MX6SX_PAD_RGMII1_TXC__ENET1_RGMII_TXC	0x0a0b9
				MX6SX_PAD_RGMII1_TD0__ENET1_TX_DATA_0	0x0a0b1
				MX6SX_PAD_RGMII1_TD1__ENET1_TX_DATA_1	0x0a0b1
				MX6SX_PAD_RGMII1_TD2__ENET1_TX_DATA_2	0x0a0b1
				MX6SX_PAD_RGMII1_TD3__ENET1_TX_DATA_3	0x0a0b1
				MX6SX_PAD_RGMII1_TX_CTL__ENET1_TX_EN	0x0a0b1
				MX6SX_PAD_RGMII1_RXC__ENET1_RX_CLK	0x03081
				MX6SX_PAD_RGMII1_RD0__ENET1_RX_DATA_0	0x03081
				MX6SX_PAD_RGMII1_RD1__ENET1_RX_DATA_1	0x03081
				MX6SX_PAD_RGMII1_RD2__ENET1_RX_DATA_2	0x03081
				MX6SX_PAD_RGMII1_RD3__ENET1_RX_DATA_3	0x03081
				MX6SX_PAD_RGMII1_RX_CTL__ENET1_RX_EN	0x03081
			>;
		};
#endif

#ifdef CONFIG_PICOCOREMX6SX_ETH1
		pinctrl_enet2: enet2grp {
			fsl,pins = <
				/* FEC2 uses MDIO bus from FEC1 */
				MX6SX_PAD_RGMII2_TXC__ENET2_RGMII_TXC	0x0a0b9
				MX6SX_PAD_RGMII2_TD0__ENET2_TX_DATA_0	0x0a0b1
				MX6SX_PAD_RGMII2_TD1__ENET2_TX_DATA_1	0x0a0b1
				MX6SX_PAD_RGMII2_TD2__ENET2_TX_DATA_2	0x0a0b1
				MX6SX_PAD_RGMII2_TD3__ENET2_TX_DATA_3	0x0a0b1
				MX6SX_PAD_RGMII2_TX_CTL__ENET2_TX_EN	0x0a0b1
				MX6SX_PAD_RGMII2_RXC__ENET2_RX_CLK	0x03081
				MX6SX_PAD_RGMII2_RD0__ENET2_RX_DATA_0	0x03081
				MX6SX_PAD_RGMII2_RD1__ENET2_RX_DATA_1	0x03081
				MX6SX_PAD_RGMII2_RD2__ENET2_RX_DATA_2	0x03081
				MX6SX_PAD_RGMII2_RD3__ENET2_RX_DATA_3	0x03081
				MX6SX_PAD_RGMII2_RX_CTL__ENET2_RX_EN	0x03081
			>;
		};
#endif

#if CONFIG_PICOCOREMX6SX_LCDIF0 == DISPLAY_LCD
		pinctrl_lcdif1: lcdgrp {
			fsl,pins = <
				MX6SX_PAD_LCD1_CLK__LCDIF1_CLK		0x000b0
				MX6SX_PAD_LCD1_DATA00__LCDIF1_DATA_0	0x000b0
				MX6SX_PAD_LCD1_DATA01__LCDIF1_DATA_1	0x000b0
				MX6SX_PAD_LCD1_DATA02__LCDIF1_DATA_2	0x000b0
				MX6SX_PAD_LCD1_DATA03__LCDIF1_DATA_3	0x000b0
				MX6SX_PAD_LCD1_DATA04__LCDIF1_DATA_4	0x000b0
				MX6SX_PAD_LCD1_DATA05__LCDIF1_DATA_5	0x000b0
				MX6SX_PAD_LCD1_DATA06__LCDIF1_DATA_6	0x000b0
				MX6SX_PAD_LCD1_DATA07__LCDIF1_DATA_7	0x000b0
				MX6SX_PAD_LCD1_DATA08__LCDIF1_DATA_8	0x000b0
				MX6SX_PAD_LCD1_DATA09__LCDIF1_DATA_9	0x000b0
				MX6SX_PAD_LCD1_DATA10__LCDIF1_DATA_10	0x000b0
				MX6SX_PAD_LCD1_DATA11__LCDIF1_DATA_11	0x000b0
				MX6SX_PAD_LCD1_DATA12__LCDIF1_DATA_12	0x000b0
				MX6SX_PAD_LCD1_DATA13__LCDIF1_DATA_13	0x000b0
				MX6SX_PAD_LCD1_DATA14__LCDIF1_DATA_14	0x000b0
				MX6SX_PAD_LCD1_DATA15__LCDIF1_DATA_15	0x000b0
				MX6SX_PAD_LCD1_DATA16__LCDIF1_DATA_16	0x000b0
				MX6SX_PAD_LCD1_DATA17__LCDIF1_DATA_17	0x000b0
				MX6SX_PAD_LCD1_DATA18__LCDIF1_DATA_18	0x000b0
				MX6SX_PAD_LCD1_DATA19__LCDIF1_DATA_19	0x000b0
				MX6SX_PAD_LCD1_DATA20__LCDIF1_DATA_20	0x000b0
				MX6SX_PAD_LCD1_DATA21__LCDIF1_DATA_21	0x000b0
				MX6SX_PAD_LCD1_DATA22__LCDIF1_DATA_22	0x000b0
				MX6SX_PAD_LCD1_DATA23__LCDIF1_DATA_23	0x000b0
				MX6SX_PAD_LCD1_ENABLE__LCDIF1_ENABLE	0x000b0
				MX6SX_PAD_LCD1_HSYNC__LCDIF1_HSYNC	0x000b0
				MX6SX_PAD_LCD1_VSYNC__LCDIF1_VSYNC	0x000b0
			>;
		};
#endif

#ifdef CONFIG_PICOCOREMX6SX_CAN_A
		pinctrl_flexcan1: flexcan1grp {
			fsl,pins = <
				MX6SX_PAD_SD3_DATA5__CAN1_TX		0x1b020
				MX6SX_PAD_SD3_DATA7__CAN1_RX		0x1b020
			>;
		};
#endif

#if 0
		pinctrl_gpmi_nand: gpmi-nand {
			/* Already configured in NBoot/U-Boot */
			fsl,pins = <
				MX6SX_PAD_NAND_CLE__RAWNAND_CLE		0x0b0b1
				MX6SX_PAD_NAND_ALE__RAWNAND_ALE		0x0b0b1
				MX6SX_PAD_NAND_WP_B__RAWNAND_WP_B	0x0b0b1
				MX6SX_PAD_NAND_READY_B__RAWNAND_READY_B	0x0b000
				MX6SX_PAD_NAND_CE0_B__RAWNAND_CE0_B	0x0b0b1
				//MX6SX_PAD_NAND_CE1_B__RAWNAND_CE1_B	0x0b0b1
				MX6SX_PAD_NAND_RE_B__RAWNAND_RE_B	0x0b0b1
				MX6SX_PAD_NAND_WE_B__RAWNAND_WE_B	0x0b0b1
				MX6SX_PAD_NAND_DATA00__RAWNAND_DATA00	0x0b0b1
				MX6SX_PAD_NAND_DATA01__RAWNAND_DATA01	0x0b0b1
				MX6SX_PAD_NAND_DATA02__RAWNAND_DATA02	0x0b0b1
				MX6SX_PAD_NAND_DATA03__RAWNAND_DATA03	0x0b0b1
				MX6SX_PAD_NAND_DATA04__RAWNAND_DATA04	0x0b0b1
				MX6SX_PAD_NAND_DATA05__RAWNAND_DATA05	0x0b0b1
				MX6SX_PAD_NAND_DATA06__RAWNAND_DATA06	0x0b0b1
				MX6SX_PAD_NAND_DATA07__RAWNAND_DATA07	0x0b0b1
			>;
		};
#endif

#ifdef CONFIG_PICOCOREMX6SX_I2C_A
		/* I2C_A: RGB-Connector (SKIT -> SX8655, LED-driver PCA9632),
		   Touch Connector (SKIT -> FT5x06, MXT), SX8655 (SKIT),
		   Feature Connector (SKIT) */
		pinctrl_i2c4: i2c4grp {
			fsl,pins = <
				MX6SX_PAD_SD3_DATA0__I2C4_SCL		0x4001b8b1
				MX6SX_PAD_SD3_DATA1__I2C4_SDA		0x4001b8b1
			>;
		};
#endif

#ifdef CONFIG_PICOCOREMX6SX_I2C_B
		/* I2C_A: RGB-Connector (SKIT -> SX8655, LED-driver PCA9632),
		   Touch Connector (SKIT -> FT5x06, MXT), SX8655 (SKIT),
		   Feature Connector (SKIT) */
		pinctrl_i2c2: i2c2grp {
			fsl,pins = <
				MX6SX_PAD_GPIO1_IO03__I2C2_SDA		0x4001b8b1
				MX6SX_PAD_GPIO1_IO02__I2C2_SCL		0x4001b8b1
			>;
		};
#endif

#ifdef CONFIG_PICOCOREMX6SX_I2C_C
		/* I2C_C: RTC (PCA8565), LVDS-Connector, SGTL5000 (SKIT) */
		pinctrl_i2c1: i2c1grp {
			fsl,pins = <
				MX6SX_PAD_GPIO1_IO01__I2C1_SDA		0x4001b8b1
				MX6SX_PAD_GPIO1_IO00__I2C1_SCL		0x4001b8b1
			>;
		};
#endif

#ifdef CONFIG_PICOCOREMX6SX_SPI_A
		pinctrl_ecspi5: ecspi5grp {
			fsl,pins = <
				MX6SX_PAD_QSPI1B_SS1_B__ECSPI5_SCLK	0x100b1
				MX6SX_PAD_QSPI1A_DQS__ECSPI5_MOSI	0x100b1
				MX6SX_PAD_QSPI1A_SS1_B__ECSPI5_MISO	0x100b1
				MX6SX_PAD_QSPI1B_DQS__GPIO4_IO_28	0x1b0b0
			>;
		};
#endif

#ifdef CONFIG_PICOCOREMX6SX_PWM_A
		/* PWM_A implemented by PWM4 */
		pinctrl_pwm4: pwm4grp {
			fsl,pins = <
				MX6SX_PAD_GPIO1_IO13__PWM4_OUT		0x110b0
			>;
		};
#endif /* CONFIG_PICOCOREMX6SX_PWM_A */

#ifdef CONFIG_PICOCOREMX6SX_BL_CTRL
		/* Backlight PWM implemented by PWM2 */
		pinctrl_pwm2: pwm2grp {
			fsl,pins = <
				MX6SX_PAD_GPIO1_IO11__PWM2_OUT		0x110b0
			>;
		};
#endif /* CONFIG_PICOCOREMX6SX_BL_CTRL */

#ifdef CONFIG_PICOCOREMX6SX_UART_A
		pinctrl_uart1: uart1grp {
			fsl,pins = <
				MX6SX_PAD_GPIO1_IO04__UART1_TX		0x1b0b1
				MX6SX_PAD_GPIO1_IO05__UART1_RX		0x1b0b1
			>;
		};
#endif

#ifdef CONFIG_PICOCOREMX6SX_UART_B
		pinctrl_uart3: uart3grp {
			fsl,pins = <
				MX6SX_PAD_QSPI1B_SS0_B__UART3_TX	0x1b0b1
				MX6SX_PAD_QSPI1B_SCLK__UART3_RX		0x1b0b1
			>;
		};
#endif

#ifdef CONFIG_PICOCOREMX6SX_UART_C
		pinctrl_uart4: uart4grp {
			fsl,pins = <
				MX6SX_PAD_SD3_DATA3__UART4_RX		0x1b0b1
				MX6SX_PAD_SD3_CMD__UART4_TX		0x1b0b1
#ifdef CONFIG_PICOCOREMX6SX_UART_C_RTSCTS
				MX6SX_PAD_SD3_DATA2__UART4_CTS_B	0x1b0b1
				MX6SX_PAD_SD3_CLK__UART4_RTS_B		0x1b0b1
#endif
			>;
		};
#endif

#ifdef CONFIG_PICOCOREMX6SX_UART_D
		pinctrl_uart2: uart2grp {
			fsl,pins = <
				MX6SX_PAD_GPIO1_IO06__UART2_TX		0x1b0b1
				MX6SX_PAD_GPIO1_IO07__UART2_RX		0x1b0b1
			>;
		};
#endif

#ifdef CONFIG_PICOCOREMX6SX_UART_E
		pinctrl_uart5: uart5grp {
			fsl,pins = <
				MX6SX_PAD_SD4_DATA4__UART5_RX		0x1b0b1
				MX6SX_PAD_SD4_DATA5__UART5_TX		0x1b0b1
#ifdef CONFIG_PICOCOREMX6SX_UART_E_RTSCTS
				MX6SX_PAD_SD4_DATA6__UART5_CTS_B	0x1b0b1
				MX6SX_PAD_SD4_DATA7__UART5_RTS_B	0x1b0b1
#endif
			>;
		};
#endif

#ifdef CONFIG_PICOCOREMX6SX_USB_OTG1
		pinctrl_usbotg1: usbotg1grp {
			fsl,pins = <
				/* USB_OTG1_PWR, active high */
				MX6SX_PAD_GPIO1_IO09__GPIO1_IO_9	0x03030
/* USB_OTG1_PWR doesnt work through HW design, need to set as GPIO */
//###				MX6SX_PAD_GPIO1_IO09__USB_OTG1_PWR	0x03030
				/* USB_OTG1_ID: low: host, open: device */
				MX6SX_PAD_GPIO1_IO10__ANATOP_OTG1_ID	0x1b000
			>;
		};
#endif

#ifdef CONFIG_PICOCOREMX6SX_USB_HOST
		pinctrl_usbotg2: usbotg2grp {
			fsl,pins = <
				/* USB_OTG2_PWR, active high */
//###			MX6SX_PAD_GPIO1_IO12__GPIO1_IO_12	0x03030
				MX6SX_PAD_GPIO1_IO12__USB_OTG2_PWR	0x03030
			>;
		};
#endif

#ifdef CONFIG_PICOCOREMX6SX_SD_A
		/* Micro-SD slot on PicoCOREBBRGB-SKIT */
		pinctrl_usdhc4_sd_a: usdhc4grp-sd_a {
			fsl,pins = <
				MX6SX_PAD_SD4_CMD__USDHC4_CMD		0x170b1
				MX6SX_PAD_SD4_CLK__USDHC4_CLK		0x100b1
				MX6SX_PAD_SD4_DATA0__USDHC4_DATA0	0x170b1
				MX6SX_PAD_SD4_DATA1__USDHC4_DATA1	0x170b1
				MX6SX_PAD_SD4_DATA2__USDHC4_DATA2	0x170b1
				MX6SX_PAD_SD4_DATA3__USDHC4_DATA3	0x170b1
				MX6SX_PAD_SD4_RESET_B__USDHC4_RESET_B	0x17091
			>;
		};

		pinctrl_usdhc4_sd_a_100mhz: usdhc4grp-sd_a_100mhz {
			fsl,pins = <
				MX6SX_PAD_SD4_CMD__USDHC4_CMD		0x1f0b9
				MX6SX_PAD_SD4_CLK__USDHC4_CLK		0x100b9
				MX6SX_PAD_SD4_DATA0__USDHC4_DATA0	0x1f0b9
				MX6SX_PAD_SD4_DATA1__USDHC4_DATA1	0x170b9
				MX6SX_PAD_SD4_DATA2__USDHC4_DATA2	0x170b9
				MX6SX_PAD_SD4_DATA3__USDHC4_DATA3	0x170b9
				MX6SX_PAD_SD4_RESET_B__USDHC4_RESET_B	0x17091
			>;
		};

		pinctrl_usdhc4_sd_a_200mhz: usdhc4grp-sd_a_200mhz {
			fsl,pins = <
				MX6SX_PAD_SD4_CMD__USDHC4_CMD		0x1f0f9
				MX6SX_PAD_SD4_CLK__USDHC4_CLK		0x100f9
				MX6SX_PAD_SD4_DATA0__USDHC4_DATA0	0x1f0f9
				MX6SX_PAD_SD4_DATA1__USDHC4_DATA1	0x170f9
				MX6SX_PAD_SD4_DATA2__USDHC4_DATA2	0x170f9
				MX6SX_PAD_SD4_DATA3__USDHC4_DATA3	0x170f9
				MX6SX_PAD_SD4_RESET_B__USDHC4_RESET_B	0x17091
			>;
		};

		pinctrl_usdhc4_cdwp: usdhc4grp-cdwp {
			fsl,pins = <
#ifdef CONFIG_PICOCOREMX6SX_SD_A_CD
				/* Card Detect (CD), active low (pull-up) */
				MX6SX_PAD_KEY_COL2__GPIO2_IO_12		0x17000
#endif
#ifdef CONFIG_PICOCOREMX6SX_SD_A_WP
				/*
				 * Write Protect (WP), active high (pull-up)
				 * lock:   WP switch open, pulled high
				 * unlock: WP switch closed, connects to GND
				 */
				MX6SX_PAD_KEY_ROW2__GPIO2_IO_17		0x17000
#endif
				/* SD_A VSEL */
				MX6SX_PAD_KEY_ROW1__USDHC4_VSELECT	0x170b1
			>;
		};
#endif /* CONFIG_PICOCOREMX6SX_SD_A */

		/* EMMC */
		pinctrl_usdhc2_emmc: usdhc2grp-emmc {
			fsl,pins = <
				MX6SX_PAD_SD2_CMD__USDHC2_CMD		0x17091
				MX6SX_PAD_SD2_CLK__USDHC2_CLK		0x17091
				MX6SX_PAD_SD2_DATA0__USDHC2_DATA0	0x17091
				MX6SX_PAD_SD2_DATA1__USDHC2_DATA1	0x17091
				MX6SX_PAD_SD2_DATA2__USDHC2_DATA2	0x17091
				MX6SX_PAD_SD2_DATA3__USDHC2_DATA3	0x17091
				MX6SX_PAD_NAND_DATA04__USDHC2_DATA4	0x17091
				MX6SX_PAD_NAND_DATA05__USDHC2_DATA5	0x17091
				MX6SX_PAD_NAND_DATA06__USDHC2_DATA6	0x17091
				MX6SX_PAD_NAND_DATA07__USDHC2_DATA7	0x17091
				MX6SX_PAD_NAND_RE_B__USDHC2_RESET_B	0x17091
			>;
		};

	};
};
